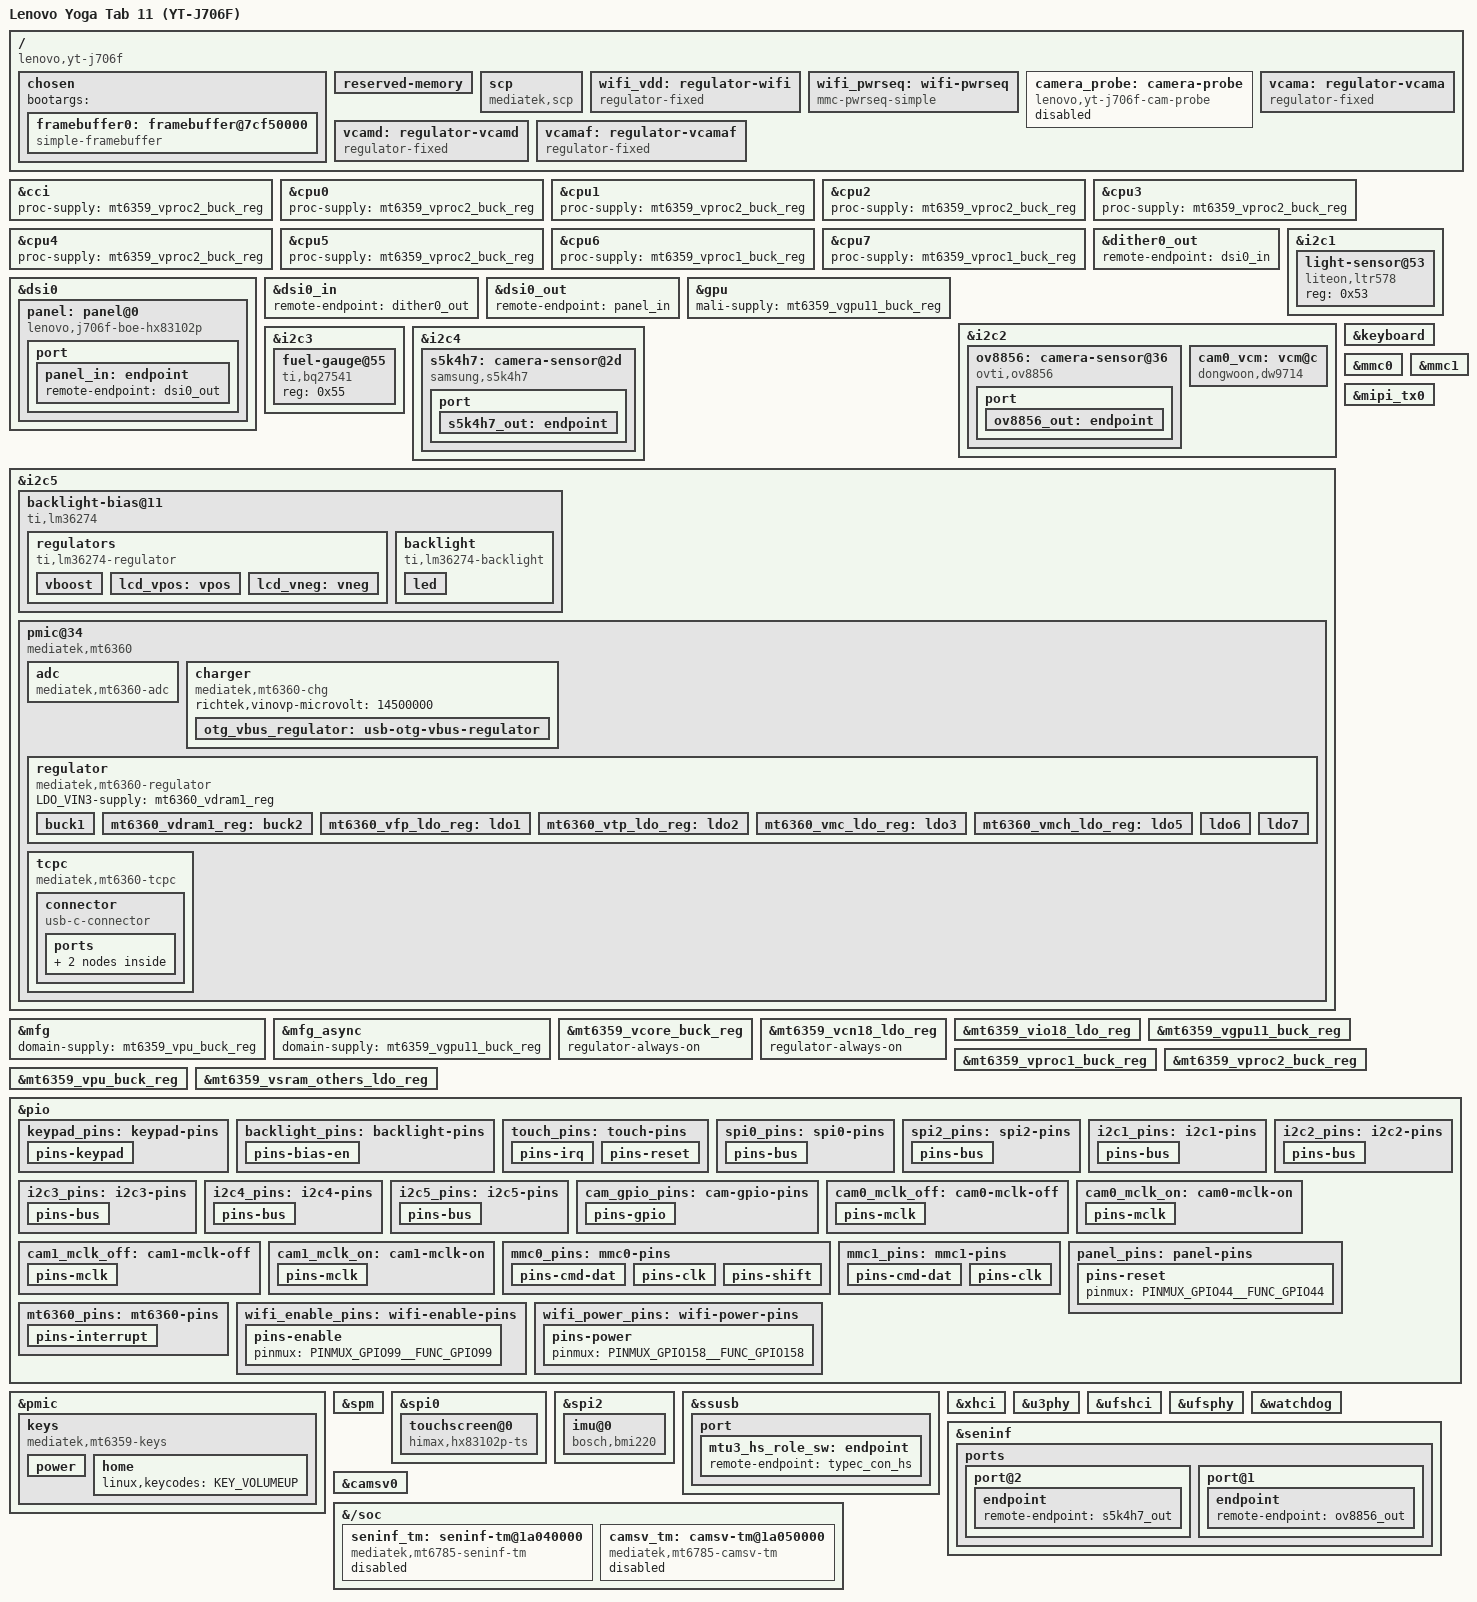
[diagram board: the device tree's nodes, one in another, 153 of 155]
// SPDX-License-Identifier: (GPL-2.0 OR MIT)
/*
 * Lenovo Yoga Tab 11 (YT-J706F), MediaTek MT6785 (Helio G90T).
 *
 * Bring-up: the bootloader's framebuffer, the watchdog, USB in
 * peripheral mode, UFS, the PMICs (MT6359, MT6360 with charger and Type-C),
 * the GPU, the fuel gauge, microSD, the MT7663 Wi-Fi/BT on SDIO and the
 * LM36274-class backlight and LCD bias. Panel, touch and audio come later. Board facts: Lenovomarchy docs/hardware/{INVENTORY,BOARD}.md.
 */

/dts-v1/;

#include <dt-bindings/gpio/gpio.h>
#include <dt-bindings/input/input.h>
#include <dt-bindings/interrupt-controller/irq.h>
#include <dt-bindings/regulator/mediatek,mt6360-regulator.h>
#include <dt-bindings/usb/pd.h>

#include "mt6785.dtsi"
#include "mt6359.dtsi"

/ {
	model = "Lenovo Yoga Tab 11 (YT-J706F)";
	compatible = "lenovo,yt-j706f", "mediatek,mt6785";
	chassis-type = "tablet";

	chosen {
		#address-cells = <2>;
		#size-cells = <2>;
		ranges;

		/* needed by Little Kernel */
		bootargs = "";

		/*
		 * The panel as LK left it: 1200x2000, BGRA8888 in memory, lines
		 * of 1216 pixels. LK passes this base (atag,videolfb-fb_base)
		 * and reserves the region itself (mblock-16-framebuffer): a
		 * reserved-memory node of ours over it makes LK's
		 * reserved_memory_conflict_check hang (seen on the unit).
		 */
		framebuffer0: framebuffer@7cf50000 {
			compatible = "simple-framebuffer";
			reg = <0 0x7cf50000 0 (4864 * 2000)>;
			width = <1200>;
			height = <2000>;
			stride = <4864>;
			format = "a8r8g8b8";
		};
	};

	/*
	 * needed by Little Kernel, which fills it with its own mblock-*
	 * nodes (framebuffer, pstore, TEE, SCP...). Do not add regions LK
	 * already manages: it stops in reserved_memory_conflict_check.
	 */
	reserved-memory {
		#address-cells = <2>;
		#size-cells = <2>;
		ranges;
	};

	/*
	 * pstore needs no node: LK passes the stock ramoops layout on the
	 * command line (ramoops.mem_address=0x4d010000, 896 KiB, console 256
	 * KiB, pmsg 64 KiB, records 4 KiB), which also lets the Android slot
	 * read a failed Linux boot's console and the other way round. A
	 * ramoops node here only fails with "already initialized".
	 */

	/* needed by Little Kernel */
	scp {
		compatible = "mediatek,scp";
	};

	/*
	 * MT7663 Wi-Fi/BT power: GPIO158 switches the module's supply (the
	 * stock kernel drives it high; with it low the chip never answers
	 * on SDIO), GPIO99 is its PMU enable, raised once powered.
	 */
	wifi_vdd: regulator-wifi {
		compatible = "regulator-fixed";
		regulator-name = "wifi_vdd";
		regulator-min-microvolt = <3300000>;
		regulator-max-microvolt = <3300000>;
		gpio = <&pio 158 GPIO_ACTIVE_HIGH>;
		enable-active-high;
		startup-delay-us = <20000>;
		vin-supply = <&mt6360_vmch_ldo_reg>;
		pinctrl-names = "default";
		pinctrl-0 = <&wifi_power_pins>;
	};

	wifi_pwrseq: wifi-pwrseq {
		compatible = "mmc-pwrseq-simple";
		reset-gpios = <&pio 99 GPIO_ACTIVE_LOW>;
		post-power-on-delay-ms = <50>;
		pinctrl-names = "default";
		pinctrl-0 = <&wifi_enable_pins>;
	};

	/*
	 * M0 camera power-up probe (driven via debugfs).  Disabled now that
	 * the real sensor node and the vcama/vcamd/vcamaf regulators own
	 * the same GPIOs: yt11-cam-probe claims them with devm_gpiod_get,
	 * which would collide with the regulators' enable GPIOs.
	 */
	camera_probe: camera-probe {
		compatible = "lenovo,yt-j706f-cam-probe";
		vcamio-supply = <&mt6359_vcamio_ldo_reg>;
		vcama-gpios = <&pio 195 GPIO_ACTIVE_HIGH>;
		vcamd-gpios = <&pio 50 GPIO_ACTIVE_HIGH>;
		vcamaf-gpios = <&pio 197 GPIO_ACTIVE_HIGH>;
		cam0-reset-gpios = <&pio 119 GPIO_ACTIVE_HIGH>;
		cam1-reset-gpios = <&pio 124 GPIO_ACTIVE_HIGH>;
		clocks = <&topckgen CLK_TOP_CAMTG1>,
			 <&topckgen CLK_TOP_CAMTG2>,
			 <&topckgen CLK_TOP_CAMTG3>,
			 <&topckgen CLK_TOP_CAMTG4>,
			 <&topckgen CLK_TOP_CAMTG5>,
			 <&topckgen CLK_TOP_UNIVPLL_192M_D8>;
		clock-names = "camtg1", "camtg2", "camtg3", "camtg4",
			      "camtg5", "src24";
		pinctrl-names = "default", "cam0_mclk_off", "cam0_mclk_on",
				"cam1_mclk_off", "cam1_mclk_on";
		pinctrl-0 = <&cam_gpio_pins>, <&cam0_mclk_off>, <&cam1_mclk_off>;
		pinctrl-1 = <&cam0_mclk_off>;
		pinctrl-2 = <&cam0_mclk_on>;
		pinctrl-3 = <&cam1_mclk_off>;
		pinctrl-4 = <&cam1_mclk_on>;
		status = "disabled";
	};

	/*
	 * Camera supply switches (docs/hardware/CAMERA.md): vcama (2.8 V
	 * analog) and vcamd (1.1 V digital) are GPIO-switched rails shared
	 * by both sensor slots, vcamaf powers the cam0 autofocus VCM.
	 * vcamio (1.8 V I/O) is the MT6359 vcamio LDO.  Each regulator
	 * holds only its own pin in pinctrl: a pinctrl state is exclusive
	 * per device, so sharing one group would make the second regulator
	 * fail its probe with -EBUSY and defer the sensor forever (seen
	 * on the first T8 boot).
	 */
	vcama: regulator-vcama {
		compatible = "regulator-fixed";
		regulator-name = "vcama";
		regulator-min-microvolt = <2800000>;
		regulator-max-microvolt = <2800000>;
		gpio = <&pio 195 GPIO_ACTIVE_HIGH>;
		enable-active-high;
	};

	vcamd: regulator-vcamd {
		compatible = "regulator-fixed";
		regulator-name = "vcamd";
		regulator-min-microvolt = <1100000>;
		regulator-max-microvolt = <1100000>;
		gpio = <&pio 50 GPIO_ACTIVE_HIGH>;
		enable-active-high;
	};

	vcamaf: regulator-vcamaf {
		compatible = "regulator-fixed";
		regulator-name = "vcamaf";
		regulator-min-microvolt = <2800000>;
		regulator-max-microvolt = <2800000>;
		gpio = <&pio 197 GPIO_ACTIVE_HIGH>;
		enable-active-high;
	};
};

&cci {
	proc-supply = <&mt6359_vproc2_buck_reg>;
};

&cpu0 {
	proc-supply = <&mt6359_vproc2_buck_reg>;
};

&cpu1 {
	proc-supply = <&mt6359_vproc2_buck_reg>;
};

&cpu2 {
	proc-supply = <&mt6359_vproc2_buck_reg>;
};

&cpu3 {
	proc-supply = <&mt6359_vproc2_buck_reg>;
};

&cpu4 {
	proc-supply = <&mt6359_vproc2_buck_reg>;
};

&cpu5 {
	proc-supply = <&mt6359_vproc2_buck_reg>;
};

&cpu6 {
	proc-supply = <&mt6359_vproc1_buck_reg>;
};

&cpu7 {
	proc-supply = <&mt6359_vproc1_buck_reg>;
};

&dither0_out {
	remote-endpoint = <&dsi0_in>;
};

/* BOE 1200x2000 on a Himax HX83102P, video mode, 4 lanes, mounted upside down */
&dsi0 {
	status = "okay";

	panel: panel@0 {
		compatible = "lenovo,j706f-boe-hx83102p";
		reg = <0>;
		/* the driver's "enable" line is the panel reset (stock: GPIO44) */
		enable-gpios = <&pio 44 GPIO_ACTIVE_HIGH>;
		pp1800-supply = <&mt6360_vtp_ldo_reg>;
		avdd-supply = <&lcd_vpos>;
		avee-supply = <&lcd_vneg>;
		/*
		 * The panel is mounted upside down, but "rotation = <180>" makes
		 * compositors ask the MT6785 OVL for a 180-degree plane rotation,
		 * which it renders as a folded, sheared picture: the compositor
		 * rotates instead (Hyprland transform 2).
		 */
		pinctrl-names = "default";
		pinctrl-0 = <&panel_pins>;

		port {
			panel_in: endpoint {
				remote-endpoint = <&dsi0_out>;
			};
		};
	};
};

&dsi0_in {
	remote-endpoint = <&dither0_out>;
};

&dsi0_out {
	remote-endpoint = <&panel_in>;
};

&gpu {
	mali-supply = <&mt6359_vgpu11_buck_reg>;
	status = "okay";
};

/*
 * Motion/light sensor bus. Stock Android drives it from the SCP sensor hub
 * (GPIO61/62 "SENSOR0_I2C"), but the pins also carry the AP's SCL1/SDA1.
 */
&i2c1 {
	clock-frequency = <100000>;
	pinctrl-names = "default";
	pinctrl-0 = <&i2c1_pins>;
	status = "okay";

	/* Lite-On LTR-578ALS (part ID 0xb1); only its light sensor is used */
	light-sensor@53 {
		compatible = "liteon,ltr578";
		reg = <0x53>;
	};
};

/*
 * Camera I2C bus 2 (stock: i2c2 @ 0x11009000, 400 kHz).  cam0 is the
 * rear OmniVision OV8856 (0x36, chip ID 0x885a; also answers at 0x21),
 * 24 MHz MCLK on GPIO117 (CMMCLK1 = CLK_TOP_CAMTG2), reset GPIO119,
 * 2 data lanes into MIPI CSI port 1 -> SENINF2 -> mux 2 -> CAMSV0
 * (docs/hardware/CAMERA.md "First frames").
 */
&i2c2 {
	clock-frequency = <400000>;
	mediatek,ch-offset = <0x100>;
	pinctrl-names = "default";
	pinctrl-0 = <&i2c2_pins>;
	status = "okay";

	ov8856: camera-sensor@36 {
		compatible = "ovti,ov8856";
		reg = <0x36>;
		clocks = <&topckgen CLK_TOP_CAMTG2>;
		assigned-clocks = <&topckgen CLK_TOP_CAMTG2>;
		assigned-clock-parents = <&topckgen CLK_TOP_UNIVPLL_192M_D8>;
		clock-names = "xvclk";
		dovdd-supply = <&mt6359_vcamio_ldo_reg>;
		avdd-supply = <&vcama>;
		dvdd-supply = <&vcamd>;
		reset-gpios = <&pio 119 GPIO_ACTIVE_LOW>;
		pinctrl-names = "default";
		pinctrl-0 = <&cam0_mclk_on>;
		/* autofocus actuator of this module (see the vcm node below) */
		lens-focus = <&cam0_vcm>;
		status = "okay";

		port {
			ov8856_out: endpoint {
				remote-endpoint = <&seninf_csi1_in>;
				data-lanes = <1 2>;
				/*
				 * 24 MHz XVCLK lane config of the (patched)
				 * ov8856 driver needs 645 + 360 MHz; 720 MHz
				 * keeps the unpatched 19.2 MHz tables probeable.
				 */
				link-frequencies = /bits/ 64 <645000000 360000000 720000000>;
			};
		};
	};

	/*
	 * Autofocus voice-coil actuator of cam0: an unidentified client at
	 * 0x0c that answers whenever the vcamaf rail (GPIO197) is on
	 * (docs/hardware/CAMERA.md).  The stock software and the begonia
	 * notes do not name the part; the DW9714 protocol (one big-endian
	 * 16-bit write, 10-bit DAC value << 4) is the common case for an
	 * unidentified 0x0c actuator and the driver performs no chip
	 * identification, so it drives any register-less DAC of that family.
	 * tools/camera/vcm-probe.py can read/write the other candidate
	 * protocols (dw9719/dw9768/ak7375) over /dev/i2c-2; if one of them
	 * identifies the part, change the compatible and the supply name to
	 * that driver's.
	 */
	cam0_vcm: vcm@c {
		compatible = "dongwoon,dw9714";
		reg = <0x0c>;
		vcc-supply = <&vcamaf>;
	};
};

/*
 * TI bq27541 fuel gauge (stock: i2c3 0x55). The stock bus runs at the
 * vendor driver's default 100 kHz; at 400 kHz the gauge's second data byte
 * often reads back as 0xff.
 */
&i2c3 {
	clock-frequency = <100000>;
	pinctrl-names = "default";
	pinctrl-0 = <&i2c3_pins>;
	status = "okay";

	fuel-gauge@55 {
		compatible = "ti,bq27541";
		reg = <0x55>;
	};
};

/*
 * Camera I2C bus 4 (stock: i2c4 @ 0x11011000, 400 kHz).  cam1 is the
 * Samsung S5K4H7 (0x2d, chip ID 0x487b; docs/research/camera/
 * T7-S5K4H7.md), 24 MHz MCLK on GPIO120 (CMMCLK2 = CLK_TOP_CAMTG3),
 * reset GPIO124, 4 data lanes, 700 Mbps/lane RAW10, sharing the
 * GPIO-switched vcama/vcamd rails with cam0 through the regulator
 * framework (reference counting, not exclusive).
 *
 * Its MIPI CSI port is NOT yet known: wired here to seninf CSI port 0
 * (SENINF0).  If the port search below says port 2 instead, move the
 * endpoint: change `remote-endpoint = <&seninf_csi0_in>` to
 * <&seninf_csi2_in> in s5k4h7_out, and point seninf port@0's endpoint
 * at nothing (delete its remote-endpoint line) while port@2 gains
 * remote-endpoint = <&s5k4h7_out>.  One line each side.
 */
&i2c4 {
	clock-frequency = <400000>;
	mediatek,ch-offset = <0x100>;
	pinctrl-names = "default";
	pinctrl-0 = <&i2c4_pins>;
	status = "okay";

	s5k4h7: camera-sensor@2d {
		compatible = "samsung,s5k4h7";
		reg = <0x2d>;
		clocks = <&topckgen CLK_TOP_CAMTG3>;
		assigned-clocks = <&topckgen CLK_TOP_CAMTG3>;
		assigned-clock-parents = <&topckgen CLK_TOP_UNIVPLL_192M_D8>;
		avdd-supply = <&vcama>;
		dovdd-supply = <&mt6359_vcamio_ldo_reg>;
		dvdd-supply = <&vcamd>;
		reset-gpios = <&pio 124 GPIO_ACTIVE_LOW>;
		pinctrl-names = "default";
		pinctrl-0 = <&cam1_mclk_on>;
		status = "okay";

		port {
			s5k4h7_out: endpoint {
				remote-endpoint = <&seninf_csi2_in>;
				data-lanes = <1 2 3 4>;
				link-frequencies = /bits/ 64 <700000000>;
			};
		};
	};
};

/*
 * i2c5: the MT6360 (same wiring as the reference design: PMU IRQ GPIO16,
 * Type-C IRQ GPIO7) and the LM36274-class backlight + LCD bias at 0x11
 * (KTZ8864A or a second-source clone).
 */
&i2c5 {
	clock-frequency = <400000>;
	pinctrl-names = "default";
	pinctrl-0 = <&i2c5_pins>;
	status = "okay";

	backlight-bias@11 {
		compatible = "ti,lm36274";
		reg = <0x11>;
		/*
		 * No enable GPIO: GPIO73, "GPIO_LCD_BL_EN" in the vendor DWS, is
		 * CONN_MIPI5_SCLK on this board (stock mt_gpio). Brightness also
		 * goes through DISP_PWM on GPIO42 (mode 1 on stock).
		 * LCD bias ENP (GPIO23) and ENN (GPIO202) stay high, as on stock.
		 */
		pinctrl-names = "default";
		pinctrl-0 = <&backlight_pins>;

		regulators {
			compatible = "ti,lm36274-regulator";

			vboost {
				regulator-name = "backlight_vboost";
				regulator-min-microvolt = <4000000>;
				regulator-max-microvolt = <7150000>;
				regulator-always-on;
			};

			/* the vendor driver sets both to 5.8 V */
			lcd_vpos: vpos {
				regulator-name = "lcd_vpos";
				regulator-min-microvolt = <5800000>;
				regulator-max-microvolt = <5800000>;
			};

			lcd_vneg: vneg {
				regulator-name = "lcd_vneg";
				regulator-min-microvolt = <5800000>;
				regulator-max-microvolt = <5800000>;
			};
		};

		backlight: backlight {
			compatible = "ti,lm36274-backlight";

			led {
				default-brightness = <800>;
				led-sources = <0 1 2>;
				max-brightness = <2047>;
				ti,exponential-mode;
				ti,ovp-microvolt = <29000000>;
			};
		};
	};

	pmic@34 {
		compatible = "mediatek,mt6360";
		reg = <0x34>;
		interrupts-extended = <&pio 16 IRQ_TYPE_EDGE_FALLING>;
		interrupt-names = "IRQB";
		interrupt-controller;
		#interrupt-cells = <1>;
		pinctrl-names = "default";
		pinctrl-0 = <&mt6360_pins>;

		adc {
			compatible = "mediatek,mt6360-adc";
			#io-channel-cells = <1>;
		};

		charger {
			compatible = "mediatek,mt6360-chg";
			richtek,vinovp-microvolt = <14500000>;

			otg_vbus_regulator: usb-otg-vbus-regulator {
				regulator-name = "usb-otg-vbus";
				regulator-min-microvolt = <4425000>;
				regulator-max-microvolt = <5825000>;
			};
		};

		regulator {
			compatible = "mediatek,mt6360-regulator";
			LDO_VIN3-supply = <&mt6360_vdram1_reg>;

			buck1 {
				regulator-name = "vapu";
				regulator-min-microvolt = <300000>;
				regulator-max-microvolt = <1300000>;
				regulator-allowed-modes = <MT6360_OPMODE_NORMAL
							   MT6360_OPMODE_LP
							   MT6360_OPMODE_ULP>;
			};

			mt6360_vdram1_reg: buck2 {
				regulator-name = "vdram1";
				regulator-min-microvolt = <300000>;
				regulator-max-microvolt = <1300000>;
				regulator-allowed-modes = <MT6360_OPMODE_NORMAL
							   MT6360_OPMODE_LP
							   MT6360_OPMODE_ULP>;
			};

			mt6360_vfp_ldo_reg: ldo1 {
				regulator-name = "vfp";
				regulator-min-microvolt = <1200000>;
				regulator-max-microvolt = <3600000>;
				regulator-allowed-modes = <MT6360_OPMODE_NORMAL
							   MT6360_OPMODE_LP>;
			};

			/* panel and touch logic ("vddi 1.8V" in the vendor driver) */
			mt6360_vtp_ldo_reg: ldo2 {
				regulator-name = "vtp";
				regulator-min-microvolt = <1800000>;
				regulator-max-microvolt = <1800000>;
				regulator-allowed-modes = <MT6360_OPMODE_NORMAL
							   MT6360_OPMODE_LP>;
				regulator-always-on;
			};

			/* SDIO I/O for the MT7663: 1.8 V only, as on the stock DT */
			mt6360_vmc_ldo_reg: ldo3 {
				regulator-name = "vmc";
				regulator-always-on;
				regulator-min-microvolt = <1800000>;
				regulator-max-microvolt = <1800000>;
				regulator-allowed-modes = <MT6360_OPMODE_NORMAL
							   MT6360_OPMODE_LP>;
			};

			mt6360_vmch_ldo_reg: ldo5 {
				regulator-name = "vmch";
				regulator-always-on;
				regulator-min-microvolt = <2700000>;
				regulator-max-microvolt = <3600000>;
				regulator-allowed-modes = <MT6360_OPMODE_NORMAL
							   MT6360_OPMODE_LP>;
			};

			ldo6 {
				regulator-name = "vmddr";
				regulator-min-microvolt = <500000>;
				regulator-max-microvolt = <2100000>;
				regulator-allowed-modes = <MT6360_OPMODE_NORMAL
							   MT6360_OPMODE_LP>;
				regulator-always-on;
			};

			ldo7 {
				regulator-name = "vdram2";
				regulator-min-microvolt = <500000>;
				regulator-max-microvolt = <2100000>;
				regulator-allowed-modes = <MT6360_OPMODE_NORMAL
							   MT6360_OPMODE_LP>;
				regulator-always-on;
			};
		};

		/* No role switch yet: USB stays a peripheral for the Mac. */
		tcpc {
			compatible = "mediatek,mt6360-tcpc";
			interrupts-extended = <&pio 7 IRQ_TYPE_EDGE_FALLING>;
			interrupt-names = "PD_IRQB";
			vbus-supply = <&otg_vbus_regulator>;

			connector {
				compatible = "usb-c-connector";
				label = "USB-C";
				data-role = "dual";
				power-role = "dual";
				try-power-role = "sink";
				op-sink-microwatt = <10000000>;
				source-pdos = <PDO_FIXED(5000, 1500,
							 PDO_FIXED_DUAL_ROLE |
							 PDO_FIXED_DATA_SWAP)>;
				sink-pdos = <PDO_FIXED(5000, 2000,
						       PDO_FIXED_DUAL_ROLE |
						       PDO_FIXED_DATA_SWAP)>;

				ports {
					#address-cells = <1>;
					#size-cells = <0>;

					port@0 {
						reg = <0>;

						typec_con_hs: endpoint {
							remote-endpoint = <&mtu3_hs_role_sw>;
						};
					};
				};
			};
		};
	};
};

/* Volume down is the keypad's only key: row 0, column 0 (stock kpd map entry 0) */
&keyboard {
	pinctrl-names = "default";
	pinctrl-0 = <&keypad_pins>;
	linux,keymap = <MATRIX_KEY(0, 0, KEY_VOLUMEDOWN)>;
	keypad,num-rows = <1>;
	keypad,num-columns = <1>;
	debounce-delay-ms = <32>;
	mediatek,keys-per-group = <1>;
	wakeup-source;
	status = "okay";
};

&mfg {
	domain-supply = <&mt6359_vpu_buck_reg>;
};

&mfg_async {
	domain-supply = <&mt6359_vgpu11_buck_reg>;
};

/* microSD (stock: mmc0 here, unlike begonia; card detect GPIO8) */
&mmc0 {
	bus-width = <4>;
	cd-gpios = <&pio 8 GPIO_ACTIVE_HIGH>;
	max-frequency = <200000000>;
	cap-sd-highspeed;
	disable-wp;
	no-mmc;
	no-sdio;
	sd-uhs-sdr50;
	sd-uhs-sdr104;
	vmmc-supply = <&mt6360_vmch_ldo_reg>;
	vqmmc-supply = <&mt6360_vfp_ldo_reg>;
	pinctrl-names = "default", "state_uhs";
	pinctrl-0 = <&mmc0_pins>;
	pinctrl-1 = <&mmc0_pins>;
	status = "okay";
};

/* MT7663 Wi-Fi (function 1) and Bluetooth (function 2) on SDIO */
&mmc1 {
	bus-width = <4>;
	max-frequency = <200000000>;
	cap-sd-highspeed;
	cap-sdio-irq;
	keep-power-in-suspend;
	non-removable;
	no-mmc;
	no-sd;
	sd-uhs-sdr50;
	sd-uhs-sdr104;
	vmmc-supply = <&wifi_vdd>;
	vqmmc-supply = <&mt6360_vmc_ldo_reg>;
	mmc-pwrseq = <&wifi_pwrseq>;
	pinctrl-names = "default", "state_uhs";
	pinctrl-0 = <&mmc1_pins>;
	pinctrl-1 = <&mmc1_pins>;
	status = "okay";
};

&mt6359_vcore_buck_reg {
	regulator-always-on;
};

/*
 * The stock overlay keeps vcn18 and vio18 always on (1.8 V); the MT7663
 * stops answering on SDIO once the regulator core switches vcn18 off as
 * unused.
 */
&mipi_tx0 {
	status = "okay";
};

&mt6359_vcn18_ldo_reg {
	regulator-always-on;
};

&mt6359_vio18_ldo_reg {
	regulator-min-microvolt = <1800000>;
	regulator-max-microvolt = <1800000>;
	regulator-always-on;
};

&mt6359_vgpu11_buck_reg {
	regulator-name = "vgpu";
	regulator-min-microvolt = <550000>;
	regulator-max-microvolt = <875000>;

	regulator-coupled-with = <&mt6359_vpu_buck_reg>;
	regulator-coupled-max-spread = <100000>;
};

&mt6359_vproc1_buck_reg {
	regulator-name = "vproc_b";
	regulator-always-on;
};

&mt6359_vproc2_buck_reg {
	regulator-name = "vproc_l";
	regulator-always-on;
};

&mt6359_vpu_buck_reg {
	regulator-name = "vsram_gpu";
	regulator-min-microvolt = <850000>;
	regulator-max-microvolt = <975000>;

	regulator-coupled-with = <&mt6359_vgpu11_buck_reg>;
	regulator-coupled-max-spread = <100000>;
};

&mt6359_vsram_others_ldo_reg {
	regulator-name = "vsram_core";
	regulator-always-on;
};

&pio {
	keypad_pins: keypad-pins {
		pins-keypad {
			pinmux = <PINMUX_GPIO58__FUNC_KPROW0>,
				 <PINMUX_GPIO59__FUNC_KPCOL0>;
		};
	};

	backlight_pins: backlight-pins {
		pins-bias-en {
			pinmux = <PINMUX_GPIO23__FUNC_GPIO23>,
				 <PINMUX_GPIO202__FUNC_GPIO202>;
			output-high;
		};
	};

	touch_pins: touch-pins {
		pins-irq {
			pinmux = <PINMUX_GPIO1__FUNC_GPIO1>;
			input-enable;
			bias-pull-up;
		};

		pins-reset {
			pinmux = <PINMUX_GPIO2__FUNC_GPIO2>;
			output-high;
		};
	};

	spi0_pins: spi0-pins {
		pins-bus {
			pinmux = <PINMUX_GPIO17__FUNC_SPI0_A_MI>,
				 <PINMUX_GPIO18__FUNC_SPI0_A_MO>,
				 <PINMUX_GPIO19__FUNC_SPI0_A_CSB>,
				 <PINMUX_GPIO20__FUNC_SPI0_A_CLK>;
		};
	};

	spi2_pins: spi2-pins {
		pins-bus {
			pinmux = <PINMUX_GPIO63__FUNC_SPI2_MI>,
				 <PINMUX_GPIO64__FUNC_SPI2_CSB>,
				 <PINMUX_GPIO65__FUNC_SPI2_MO>,
				 <PINMUX_GPIO66__FUNC_SPI2_CLK>;
		};
	};

	i2c1_pins: i2c1-pins {
		pins-bus {
			pinmux = <PINMUX_GPIO61__FUNC_SCL1>,
				 <PINMUX_GPIO62__FUNC_SDA1>;
			bias-pull-up;
		};
	};

	i2c2_pins: i2c2-pins {
		pins-bus {
			pinmux = <PINMUX_GPIO112__FUNC_SCL2>,
				 <PINMUX_GPIO113__FUNC_SDA2>;
			bias-pull-up;
		};
	};

	i2c3_pins: i2c3-pins {
		pins-bus {
			pinmux = <PINMUX_GPIO55__FUNC_SCL3>,
				 <PINMUX_GPIO56__FUNC_SDA3>;
			bias-pull-up;
		};
	};

	i2c4_pins: i2c4-pins {
		pins-bus {
			pinmux = <PINMUX_GPIO110__FUNC_SCL4>,
				 <PINMUX_GPIO111__FUNC_SDA4>;
			bias-pull-up;
		};
	};

	i2c5_pins: i2c5-pins {
		pins-bus {
			pinmux = <PINMUX_GPIO28__FUNC_SCL5>,
				 <PINMUX_GPIO29__FUNC_SDA5>;
			bias-pull-up;
		};
	};

	cam_gpio_pins: cam-gpio-pins {
		pins-gpio {
			pinmux = <PINMUX_GPIO50__FUNC_GPIO50>,
				 <PINMUX_GPIO119__FUNC_GPIO119>,
				 <PINMUX_GPIO124__FUNC_GPIO124>,
				 <PINMUX_GPIO195__FUNC_GPIO195>,
				 <PINMUX_GPIO197__FUNC_GPIO197>;
			output-low;
		};
	};

	cam0_mclk_off: cam0-mclk-off {
		pins-mclk {
			pinmux = <PINMUX_GPIO117__FUNC_GPIO117>;
			output-low;
		};
	};

	cam0_mclk_on: cam0-mclk-on {
		pins-mclk {
			pinmux = <PINMUX_GPIO117__FUNC_CMMCLK1>;
			drive-strength = <4>;
		};
	};

	cam1_mclk_off: cam1-mclk-off {
		pins-mclk {
			pinmux = <PINMUX_GPIO120__FUNC_GPIO120>;
			output-low;
		};
	};

	cam1_mclk_on: cam1-mclk-on {
		pins-mclk {
			pinmux = <PINMUX_GPIO120__FUNC_CMMCLK2>;
			drive-strength = <4>;
		};
	};

	mmc0_pins: mmc0-pins {
		pins-cmd-dat {
			pinmux = <PINMUX_GPIO167__FUNC_MSDC0_CMD>,
				 <PINMUX_GPIO168__FUNC_MSDC0_DAT0>,
				 <PINMUX_GPIO172__FUNC_MSDC0_DAT1>,
				 <PINMUX_GPIO169__FUNC_MSDC0_DAT2>,
				 <PINMUX_GPIO177__FUNC_MSDC0_DAT3>;
			bias-pull-up = <MTK_PUPD_SET_R1R0_01>;
			drive-strength = <8>;
			input-enable;
		};

		pins-clk {
			pinmux = <PINMUX_GPIO176__FUNC_MSDC0_CLK>;
			bias-pull-down = <MTK_PUPD_SET_R1R0_10>;
			drive-strength = <8>;
		};

		/* stock "pins_shift": a level shifter enable, held low */
		pins-shift {
			pinmux = <PINMUX_GPIO47__FUNC_GPIO47>;
			output-low;
		};
	};

	mmc1_pins: mmc1-pins {
		pins-cmd-dat {
			pinmux = <PINMUX_GPIO135__FUNC_MSDC1_CMD>,
				 <PINMUX_GPIO137__FUNC_MSDC1_DAT0>,
				 <PINMUX_GPIO139__FUNC_MSDC1_DAT1>,
				 <PINMUX_GPIO138__FUNC_MSDC1_DAT2>,
				 <PINMUX_GPIO136__FUNC_MSDC1_DAT3>;
			bias-pull-up = <MTK_PUPD_SET_R1R0_01>;
			drive-strength = <8>;
			input-enable;
		};

		pins-clk {
			pinmux = <PINMUX_GPIO134__FUNC_MSDC1_CLK>;
			bias-pull-down = <MTK_PUPD_SET_R1R0_10>;
			drive-strength = <8>;
		};
	};

	panel_pins: panel-pins {
		pins-reset {
			pinmux = <PINMUX_GPIO44__FUNC_GPIO44>;
		};
	};

	mt6360_pins: mt6360-pins {
		pins-interrupt {
			pinmux = <PINMUX_GPIO7__FUNC_GPIO7>,
				 <PINMUX_GPIO16__FUNC_GPIO16>;
			bias-pull-up;
			input-enable;
		};
	};

	wifi_enable_pins: wifi-enable-pins {
		pins-enable {
			pinmux = <PINMUX_GPIO99__FUNC_GPIO99>;
		};
	};

	wifi_power_pins: wifi-power-pins {
		pins-power {
			pinmux = <PINMUX_GPIO158__FUNC_GPIO158>;
		};
	};
};

&pmic {
	/* stock: EINT 193, level high, as on the reference design */
	interrupts-extended = <&pio 193 IRQ_TYPE_LEVEL_HIGH>;

	keys {
		compatible = "mediatek,mt6359-keys";

		power {
			linux,keycodes = <KEY_POWER>;
			wakeup-source;
		};

		/* the PMIC "home" key is Volume Up on this tablet */
		home {
			linux,keycodes = <KEY_VOLUMEUP>;
		};
	};
};

/*
 * Peripheral only for now: USB networking and serial to the Mac. The
 * MT6360 Type-C controller and host mode come with the charger.
 */
/*
 * MT8789 (the Wi-Fi-only MT6785, "wifi only IC, no modem" in LK's log): the
 * modem domain never powers on, and its timeout (-110) made the whole power
 * controller fail its probe on the first boot.
 */
&spm {
	/delete-node/ power-domain@4;
};

/* Himax HX83102P touch and pen, the touch side of the panel's TDDI chip */
&spi0 {
	pinctrl-names = "default";
	pinctrl-0 = <&spi0_pins>;
	mediatek,pad-select = <0>;
	status = "okay";

	touchscreen@0 {
		compatible = "himax,hx83102p-ts";
		reg = <0>;
		spi-max-frequency = <9600000>;
		interrupts-extended = <&pio 1 IRQ_TYPE_EDGE_FALLING>;
		reset-gpios = <&pio 2 GPIO_ACTIVE_LOW>;
		panel = <&panel>;
		touchscreen-size-x = <1200>;
		touchscreen-size-y = <2000>;
		pinctrl-names = "default";
		pinctrl-0 = <&touch_pins>;
	};
};

/*
 * Bosch BMI220 accelerometer + gyroscope (chip id 0x26). Stock Android
 * drives it from the SCP's SPI2; the same pins carry the AP's SPI2. The
 * supplies are not described by the stock DT (the SCP owned the chip);
 * the chip answers with the always-on 1.8 V VIO18, assumed for both.
 */
&spi2 {
	pinctrl-names = "default";
	pinctrl-0 = <&spi2_pins>;
	mediatek,pad-select = <0>;
	status = "okay";

	imu@0 {
		compatible = "bosch,bmi220";
		reg = <0>;
		spi-max-frequency = <1000000>;
		vdd-supply = <&mt6359_vio18_ldo_reg>;
		vddio-supply = <&mt6359_vio18_ldo_reg>;
	};
};

/*
 * USB-C through the MT6360 TCPC: TCPM sets the data role, so unplugging
 * the cable disconnects the gadget (otherwise mtu3 believes a host is still
 * attached and refuses system suspend). Peripheral until TCPM decides, for
 * the USB network access at boot.
 */
&ssusb {
	dr_mode = "otg";
	maximum-speed = "high-speed";
	usb-role-switch;
	role-switch-default-mode = "peripheral";
	vusb33-supply = <&mt6359_vusb_ldo_reg>;
	status = "okay";

	port {
		mtu3_hs_role_sw: endpoint {
			remote-endpoint = <&typec_con_hs>;
		};
	};
};

&xhci {
	status = "okay";
};

&u3phy {
	status = "okay";
};

&ufshci {
	mediatek,ufs-disable-mcq;
	mediatek,ufs-support-va09;

	va09-supply = <&mt6359_va09_ldo_reg>;
	vcc-supply = <&mt6359_vemc_ldo_reg>;
	vccq2-supply = <&mt6359_vufs_ldo_reg>;

	status = "okay";
};

&ufsphy {
	status = "okay";
};

&watchdog {
	status = "okay";
};

/*
 * Real camera pipeline: mt6785-cam drivers (SENINF CSI-2 receiver +
 * CAMSV0 raw capture).  The M2 experiment nodes below are kept but
 * disabled: they map the same SENINF/CAMSV0 register windows.
 */
&seninf {
	status = "okay";

	ports {
		/* cam1 S5K4H7: trying CSI port 2 (port 0 carried no packets). */
		port@2 {
			endpoint {
				remote-endpoint = <&s5k4h7_out>;
			};
		};
		port@1 {
			endpoint {
				remote-endpoint = <&ov8856_out>;
			};
		};
	};
};

&camsv0 {
	status = "okay";
};

/*
 * M2 camera bring-up test-model nodes (SoC SENINF + CAMSV0 + MIPI RX
 * ANA/CDPHY).  Disabled now that the real mt6785-cam drivers own the
 * same register windows and clocks; keep the nodes for the experiment
 * modules' documentation value.
 */
&{/soc} {
	seninf_tm: seninf-tm@1a040000 {
		compatible = "mediatek,mt6785-seninf-tm";
		reg = <0 0x1a040000 0 0x6000>;
		power-domains = <&spm MT6785_POWER_DOMAIN_CAM>,
				<&spm MT6785_POWER_DOMAIN_ISP>;
		power-domain-names = "cam", "isp";
		clocks = <&camsys CLK_CAM_MAIN>,
			 <&camsys CLK_CAM_GALS>,
			 <&camsys CLK_CAM_TG>,
			 <&camsys CLK_CAM_SENINF>,
			 <&topckgen CLK_TOP_SENINF0>,
			 <&topckgen CLK_TOP_SENINF1>,
			 <&topckgen CLK_TOP_SENINF2>;
		clock-names = "cam-main", "cam-gals", "cam-tg", "cam-seninf",
			      "top-seninf0", "top-seninf1", "top-seninf2";
		status = "disabled";
	};

	camsv_tm: camsv-tm@1a050000 {
		compatible = "mediatek,mt6785-camsv-tm";
		reg = <0 0x1a040000 0 0x6000>,	/* SENINF */
		      <0 0x1a050000 0 0x1000>,	/* CAMSV0 */
		      <0 0x1a000000 0 0x1000>,	/* camsys */
		      <0 0x11c80000 0 0xc000>;	/* MIPI RX ANA/CDPHY (CSI0..2) */
		power-domains = <&spm MT6785_POWER_DOMAIN_CAM>,
				<&spm MT6785_POWER_DOMAIN_ISP>;
		power-domain-names = "cam", "isp";
		clocks = <&camsys CLK_CAM_MAIN>,
			 <&camsys CLK_CAM_GALS>,
			 <&camsys CLK_CAM_TG>,
			 <&camsys CLK_CAM_SENINF>,
			 <&camsys CLK_CAM_SV0>,
			 <&camsys CLK_CAM_SV1>,
			 <&camsys CLK_CAM_LARB6>,
			 <&camsys CLK_CAM_LARB7>,
			 <&topckgen CLK_TOP_SENINF0>,
			 <&topckgen CLK_TOP_SENINF1>,
			 <&topckgen CLK_TOP_SENINF2>,
			 <&apmixedsys CLK_APMIXED_MIPIC0>,
			 <&apmixedsys CLK_APMIXED_MIPIC1>;
		clock-names = "cam-main", "cam-gals", "cam-tg", "cam-seninf",
			      "cam-sv0", "cam-sv1", "cam-larb6", "cam-larb7",
			      "top-seninf0", "top-seninf1", "top-seninf2",
			      "mipic0", "mipic1";
		mediatek,larb = <&larb6>;
		status = "disabled";
	};
};

#include "mt6785-lenovo-yt-j706f-audio.dtsi"
